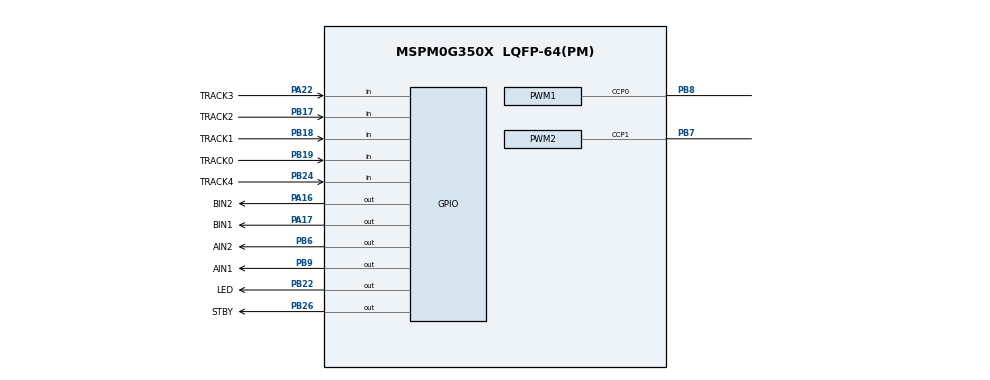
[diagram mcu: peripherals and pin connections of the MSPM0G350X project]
/**
 * @cliArgs --device "MSPM0G350X" --part "Default" --package "LQFP-64(PM)" --product "mspm0_sdk@2.11.00.07"
 * @versions {"tool":"1.26.2+4477"}
 */

/**
 * Import the modules used in this configuration.
 */
const GPIO   = scripting.addModule("/ti/driverlib/GPIO", {}, false);
const GPIO1  = GPIO.addInstance();
const GPIO2  = GPIO.addInstance();
const PWM    = scripting.addModule("/ti/driverlib/PWM", {}, false);
const PWM1   = PWM.addInstance();
const PWM2   = PWM.addInstance();
const SYSCTL = scripting.addModule("/ti/driverlib/SYSCTL");

/**
 * Write custom configuration values to the imported modules.
 */
const divider9       = system.clockTree["UDIV"];
divider9.divideValue = 2;

const multiplier2         = system.clockTree["PLL_QDIV"];
multiplier2.multiplyValue = 5;

const mux4       = system.clockTree["EXHFMUX"];
mux4.inputSelect = "EXHFMUX_XTAL";

const mux5       = system.clockTree["EXLFMUX"];
mux5.inputSelect = "EXLFMUX_XTAL";

const mux8       = system.clockTree["HSCLKMUX"];
mux8.inputSelect = "HSCLKMUX_SYSPLL0";

const pinFunction4     = system.clockTree["HFXT"];
pinFunction4.inputFreq = 40;
pinFunction4.enable    = true;

GPIO1.$name                         = "MOTOR";
GPIO1.associatedPins.create(6);
GPIO1.associatedPins[0].$name       = "BIN2";
GPIO1.associatedPins[0].ioStructure = "SD";
GPIO1.associatedPins[0].pin.$assign = "PA16";
GPIO1.associatedPins[1].ioStructure = "SDW";
GPIO1.associatedPins[1].$name       = "BIN1";
GPIO1.associatedPins[1].pin.$assign = "PA17";
GPIO1.associatedPins[2].$name       = "STBY";
GPIO1.associatedPins[2].ioStructure = "SD";
GPIO1.associatedPins[2].pin.$assign = "PB26";
GPIO1.associatedPins[3].$name       = "AIN1";
GPIO1.associatedPins[3].ioStructure = "SD";
GPIO1.associatedPins[3].pin.$assign = "PB9";
GPIO1.associatedPins[4].$name       = "AIN2";
GPIO1.associatedPins[4].ioStructure = "SD";
GPIO1.associatedPins[4].pin.$assign = "PB6";
GPIO1.associatedPins[5].$name       = "LED";
GPIO1.associatedPins[5].ioStructure = "SD";
GPIO1.associatedPins[5].pin.$assign = "PB22";

const Board = scripting.addModule("/ti/driverlib/Board", {}, false);

GPIO2.$name                         = "TRACK";
GPIO2.associatedPins.create(5);
GPIO2.associatedPins[0].direction   = "INPUT";
GPIO2.associatedPins[0].ioStructure = "SD";
GPIO2.associatedPins[0].$name       = "TRACK0";
GPIO2.associatedPins[0].pin.$assign = "PB19";
GPIO2.associatedPins[1].direction   = "INPUT";
GPIO2.associatedPins[1].ioStructure = "SD";
GPIO2.associatedPins[1].$name       = "TRACK1";
GPIO2.associatedPins[1].pin.$assign = "PB18";
GPIO2.associatedPins[2].direction   = "INPUT";
GPIO2.associatedPins[2].ioStructure = "SD";
GPIO2.associatedPins[2].$name       = "TRACK2";
GPIO2.associatedPins[2].pin.$assign = "PB17";
GPIO2.associatedPins[3].direction   = "INPUT";
GPIO2.associatedPins[3].ioStructure = "SD";
GPIO2.associatedPins[3].$name       = "TRACK3";
GPIO2.associatedPins[3].pin.$assign = "PA22";
GPIO2.associatedPins[4].direction   = "INPUT";
GPIO2.associatedPins[4].ioStructure = "SD";
GPIO2.associatedPins[4].$name       = "TRACK4";
GPIO2.associatedPins[4].pin.$assign = "PB24";

PWM1.$name                              = "PWMB";
PWM1.pwmMode                            = "EDGE_ALIGN_UP";
PWM1.timerStartTimer                    = true;
PWM1.timerCount                         = 4000;
PWM1.clockDivider                       = 2;
PWM1.ccIndex                            = [0];
PWM1.PWM_CHANNEL_0.$name                = "ti_driverlib_pwm_PWMTimerCC0";
PWM1.ccp0PinConfig.$name                = "ti_driverlib_gpio_GPIOPinGeneric0";
PWM1.ccp0PinConfig.direction            = scripting.forceWrite("OUTPUT");
PWM1.ccp0PinConfig.hideOutputInversion  = scripting.forceWrite(false);
PWM1.ccp0PinConfig.onlyInternalResistor = scripting.forceWrite(false);
PWM1.ccp0PinConfig.passedPeripheralType = scripting.forceWrite("Digital");
PWM1.peripheral.$assign                 = "TIMA0";
PWM1.peripheral.ccp0Pin.$assign         = "PB8";

PWM2.$name                              = "PWMA";
PWM2.timerCount                         = 4000;
PWM2.pwmMode                            = "EDGE_ALIGN_UP";
PWM2.timerStartTimer                    = true;
PWM2.ccIndex                            = [1];
PWM2.clockDivider                       = 2;
PWM2.ccp1PinConfig.direction            = scripting.forceWrite("OUTPUT");
PWM2.ccp1PinConfig.hideOutputInversion  = scripting.forceWrite(false);
PWM2.ccp1PinConfig.onlyInternalResistor = scripting.forceWrite(false);
PWM2.ccp1PinConfig.passedPeripheralType = scripting.forceWrite("Digital");
PWM2.ccp1PinConfig.$name                = "ti_driverlib_gpio_GPIOPinGeneric2";
PWM2.peripheral.$assign                 = "TIMG6";
PWM2.peripheral.ccp1Pin.$assign         = "PB7";
PWM2.PWM_CHANNEL_1.$name                = "ti_driverlib_pwm_PWMTimerCC1";

SYSCTL.forceDefaultClkConfig = true;
SYSCTL.clockTreeEn           = true;

/**
 * Pinmux solution for unlocked pins/peripherals. This ensures that minor changes to the automatic solver in a future
 * version of the tool will not impact the pinmux you originally saw.  These lines can be completely deleted in order to
 * re-solve from scratch.
 */
pinFunction4.peripheral.$suggestSolution           = "SYSCTL";
pinFunction4.peripheral.hfxInPin.$suggestSolution  = "PA5";
pinFunction4.peripheral.hfxOutPin.$suggestSolution = "PA6";
Board.peripheral.$suggestSolution                  = "DEBUGSS";
Board.peripheral.swclkPin.$suggestSolution         = "PA20";
Board.peripheral.swdioPin.$suggestSolution         = "PA19";
